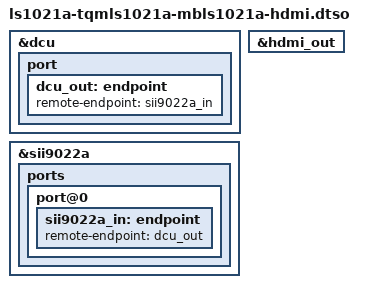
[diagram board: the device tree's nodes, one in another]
// SPDX-License-Identifier: (GPL-2.0-or-later OR X11)
/*
 * Copyright 2018-2023 TQ-Systems GmbH <linux@ew.tq-group.com>,
 * D-82229 Seefeld, Germany.
 * Author: Alexander Stein

 */

/dts-v1/;
/plugin/;

&dcu {
	status = "okay";

	port {
		dcu_out: endpoint {
			remote-endpoint = <&sii9022a_in>;
		};
	};
};

&hdmi_out {
	status = "okay";
};

&sii9022a {
	status = "okay";

	ports {
		port@0 {
			sii9022a_in: endpoint {
				remote-endpoint = <&dcu_out>;
			};
		};
	};
};
